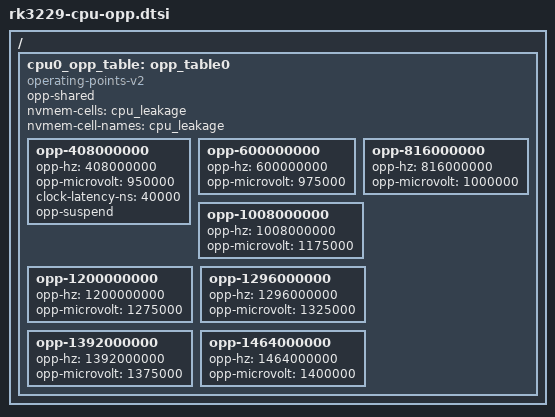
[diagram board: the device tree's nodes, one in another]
/*
 * Copyright (c) 2017 Fuzhou Rockchip Electronics Co., Ltd
 *
 * This file is dual-licensed: you can use it either under the terms
 * of the GPL or the X11 license, at your option. Note that this dual
 * licensing only applies to this file, and not this project as a
 * whole.
 *
 *  a) This library is free software; you can redistribute it and/or
 *     modify it under the terms of the GNU General Public License as
 *     published by the Free Software Foundation; either version 2 of the
 *     License, or (at your option) any later version.
 *
 *     This library is distributed in the hope that it will be useful,
 *     but WITHOUT ANY WARRANTY; without even the implied warranty of
 *     MERCHANTABILITY or FITNESS FOR A PARTICULAR PURPOSE.  See the
 *     GNU General Public License for more details.
 *
 * Or, alternatively,
 *
 *  b) Permission is hereby granted, free of charge, to any person
 *     obtaining a copy of this software and associated documentation
 *     files (the "Software"), to deal in the Software without
 *     restriction, including without limitation the rights to use,
 *     copy, modify, merge, publish, distribute, sublicense, and/or
 *     sell copies of the Software, and to permit persons to whom the
 *     Software is furnished to do so, subject to the following
 *     conditions:
 *
 *     The above copyright notice and this permission notice shall be
 *     included in all copies or substantial portions of the Software.
 *
 *     THE SOFTWARE IS PROVIDED "AS IS", WITHOUT WARRANTY OF ANY KIND,
 *     EXPRESS OR IMPLIED, INCLUDING BUT NOT LIMITED TO THE WARRANTIES
 *     OF MERCHANTABILITY, FITNESS FOR A PARTICULAR PURPOSE AND
 *     NONINFRINGEMENT. IN NO EVENT SHALL THE AUTHORS OR COPYRIGHT
 *     HOLDERS BE LIABLE FOR ANY CLAIM, DAMAGES OR OTHER LIABILITY,
 *     WHETHER IN AN ACTION OF CONTRACT, TORT OR OTHERWISE, ARISING
 *     FROM, OUT OF OR IN CONNECTION WITH THE SOFTWARE OR THE USE OR
 *     OTHER DEALINGS IN THE SOFTWARE.
 */

/ {
	/delete-node/ opp-table0;

	cpu0_opp_table: opp_table0 {
		compatible = "operating-points-v2";
		opp-shared;

		nvmem-cells = <&cpu_leakage>;
		nvmem-cell-names = "cpu_leakage";

		opp-408000000 {
			opp-hz = /bits/ 64 <408000000>;
			opp-microvolt = <950000>;
			clock-latency-ns = <40000>;
			opp-suspend;
		};
		opp-600000000 {
			opp-hz = /bits/ 64 <600000000>;
			opp-microvolt = <975000>;
		};
		opp-816000000 {
			opp-hz = /bits/ 64 <816000000>;
			opp-microvolt = <1000000>;
		};
		opp-1008000000 {
			opp-hz = /bits/ 64 <1008000000>;
			opp-microvolt = <1175000>;
		};
		opp-1200000000 {
			opp-hz = /bits/ 64 <1200000000>;
			opp-microvolt = <1275000>;
		};
		opp-1296000000 {
			opp-hz = /bits/ 64 <1296000000>;
			opp-microvolt = <1325000>;
		};
		opp-1392000000 {
			opp-hz = /bits/ 64 <1392000000>;
			opp-microvolt = <1375000>;
		};
		opp-1464000000 {
			opp-hz = /bits/ 64 <1464000000>;
			opp-microvolt = <1400000>;
		};
	};
};
